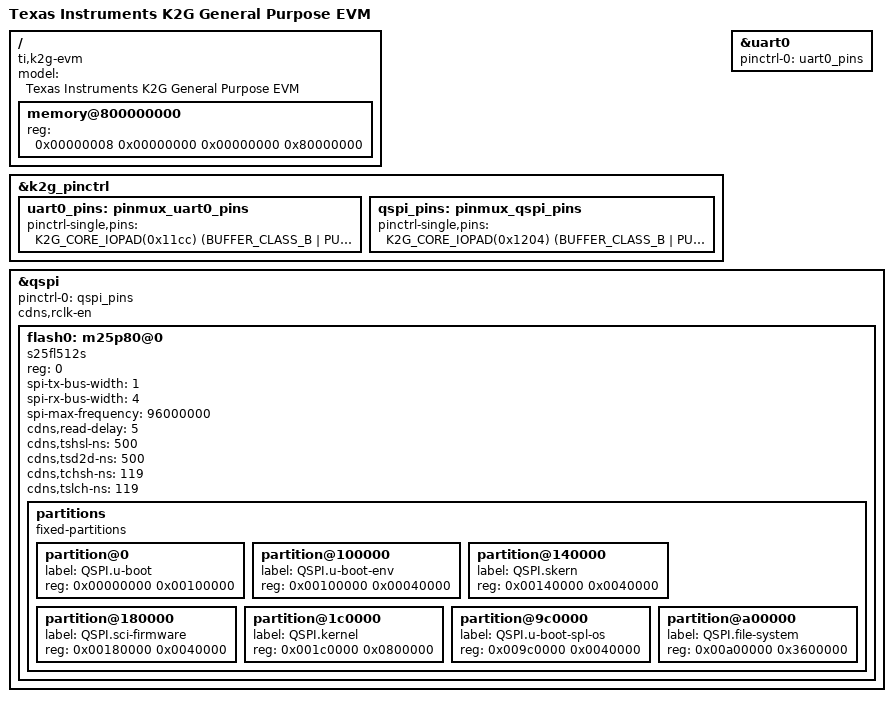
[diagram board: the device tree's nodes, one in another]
/*
 * Device Tree Source for K2G EVM
 *
 * Copyright (C) 2016 Texas Instruments Incorporated - http://www.ti.com/
 *
 * This program is free software; you can redistribute it and/or modify
 * it under the terms of the GNU General Public License version 2 as
 * published by the Free Software Foundation.
 *
 * This program is distributed "as is" WITHOUT ANY WARRANTY of any
 * kind, whether express or implied; without even the implied warranty
 * of MERCHANTABILITY or FITNESS FOR A PARTICULAR PURPOSE.  See the
 * GNU General Public License for more details.
 */
/dts-v1/;

#include "keystone-k2g.dtsi"

/ {
	compatible =  "ti,k2g-evm", "ti,k2g", "ti,keystone";
	model = "Texas Instruments K2G General Purpose EVM";

	memory@800000000 {
		device_type = "memory";
		reg = <0x00000008 0x00000000 0x00000000 0x80000000>;
	};

};

&k2g_pinctrl {
	uart0_pins: pinmux_uart0_pins {
		pinctrl-single,pins = <
			K2G_CORE_IOPAD(0x11cc) (BUFFER_CLASS_B | PULL_DISABLE | MUX_MODE0)	/* uart0_rxd.uart0_rxd */
			K2G_CORE_IOPAD(0x11d0) (BUFFER_CLASS_B | PIN_PULLDOWN | MUX_MODE0)	/* uart0_txd.uart0_txd */
		>;
	};

	qspi_pins: pinmux_qspi_pins {
		pinctrl-single,pins = <
			K2G_CORE_IOPAD(0x1204) (BUFFER_CLASS_B | PULL_DISABLE | MUX_MODE0) /* qspi_clk.qspi_clk */
			K2G_CORE_IOPAD(0x1208) (BUFFER_CLASS_B | PULL_DISABLE | MUX_MODE0) /* qspi_rclk.qspi_rclk */
			K2G_CORE_IOPAD(0x120c) (BUFFER_CLASS_B | PULL_DISABLE | MUX_MODE0) /* qspi_d0.qspi_d0 */
			K2G_CORE_IOPAD(0x1210) (BUFFER_CLASS_B | PULL_DISABLE | MUX_MODE0) /* qspi_d1.qspi_d1 */
			K2G_CORE_IOPAD(0x1214) (BUFFER_CLASS_B | PULL_DISABLE | MUX_MODE0) /* qspi_d2.qspi_d2 */
			K2G_CORE_IOPAD(0x1218) (BUFFER_CLASS_B | PULL_DISABLE | MUX_MODE0) /* qspi_d3.qspi_d3 */
			K2G_CORE_IOPAD(0x121c) (BUFFER_CLASS_B | PULL_DISABLE | MUX_MODE0) /* qspi_csn0.qspi_csn0 */
		>;
	};
};

&uart0 {
	pinctrl-names = "default";
	pinctrl-0 = <&uart0_pins>;
	status = "okay";
};

&qspi {
	pinctrl-names = "default";
	pinctrl-0 = <&qspi_pins>;
	cdns,rclk-en;
	status = "okay";

	flash0: m25p80@0 {
		compatible = "s25fl512s", "jedec,spi-nor";
		reg = <0>;
		spi-tx-bus-width = <1>;
		spi-rx-bus-width = <4>;
		spi-max-frequency = <96000000>;
		#address-cells = <1>;
		#size-cells = <1>;
		cdns,read-delay = <5>;
		cdns,tshsl-ns = <500>;
		cdns,tsd2d-ns = <500>;
		cdns,tchsh-ns = <119>;
		cdns,tslch-ns = <119>;

		partitions {
			compatible = "fixed-partitions";
			#address-cells = <1>;
			#size-cells = <1>;

			partition@0 {
				label = "QSPI.u-boot";
				reg = <0x00000000 0x00100000>;
			};
			partition@100000 {
				label = "QSPI.u-boot-env";
				reg = <0x00100000 0x00040000>;
			};
			partition@140000 {
				label = "QSPI.skern";
				reg = <0x00140000 0x0040000>;
			};
			partition@180000 {
				label = "QSPI.sci-firmware";
				reg = <0x00180000 0x0040000>;
			};
			partition@1c0000 {
				label = "QSPI.kernel";
				reg = <0x001c0000 0x0800000>;
			};
			partition@9c0000 {
				label = "QSPI.u-boot-spl-os";
				reg = <0x009c0000 0x0040000>;
			};
			partition@a00000 {
				label = "QSPI.file-system";
				reg = <0x00a00000 0x3600000>;
			};
		};
	};
};
